# ATA5795 device description
Architecture: AVR8; Family: megaAVR
Registers are 8-bit, access not given, no defined reset value unless marked. A register's access mark holds for its fields unless they carry their own. Offsets are from the block's base; [hi:lo] are bit positions.

## RTC_TIMER
Instances: RTC_TIMER 0x00
0x9E RTCCR — Real-Time Clock Control Register
  [0] RTCR — Real-Time Counter Reset Bit
0x9F RTCDR — Real Time Clock Data Register

## WDT — Watchdog Timer
Instances: WDT 0x00
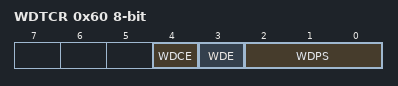
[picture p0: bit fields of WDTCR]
0x60 WDTCR — Watchdog Timer Control Register
  [4] WDCE — Watchdog Change Enable
  [3] WDE — Watch Dog Enable
  [2:0] WDPS — Watch Dog Timer Prescaler Select bits

## PORTC
Instances: PORTC 0x00
0x26 PINC bits used 4:0 — Port C Input Pins
0x27 DDRC bits used 4:0 — Port C Data Direction Register
0x28 PORTC bits used 4:0 — Port C Data Register

## CPU
Instances: CPU 0x00
Parameters: CORE_VERSION=V2E, NEW_INSTRUCTIONS=jmp k:call k
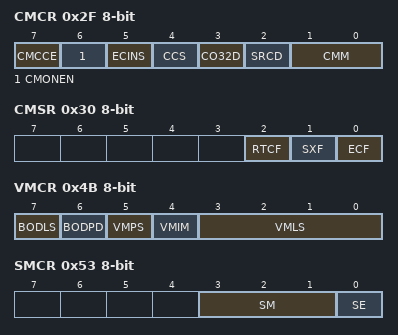
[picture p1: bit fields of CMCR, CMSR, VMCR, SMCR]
0x2F CMCR — Clock Management Control Register
  [7] CMCCE — Clock Management Control Change Enable Bit
  [6] CMONEN — Clock Monitoring Enable Bit
  [5] ECINS — External Clock Input Select Bit
  [4] CCS — Core Clock Select Bit
  [3] CO32D — Crystal Oscillator 32 kHz Disable Bit
  [2] SRCD — Slow RC-oscillator Disable Bit
  [1:0] CMM — Clock Management Mode Bitss
0x30 CMSR — Clock Management Status Register
  [2] RTCF — Real-Time Clock Flag
  [1] SXF — Slow Crystal Oscillator Flag
  [0] ECF — External Clock input Flag Bit
0x36 VMSR — Voltage Monitor Status Register
  [0] VMF — Voltage Monitor Flag
0x3E GPIOR0 — General Purpose I/O Register 0
0x4B VMCR — Voltage Monitor Control Register
  [7] BODLS — Brown-Out Detection Level Select Bit
  [6] BODPD — Brown-Out Detection on Power-Down Bit
  [5] VMPS — Voltage Monitor Power supply Select Bit
  [4] VMIM — Voltage Monitor Interrupt Mask Bit
  [3:0] VMLS — Voltage Monitor Level Select Bits
0x53 SMCR — Sleep Mode Control Register
  [3:1] SM — Sleep Mode Select Bit2
    0=IDLE; 1=EPSAVE (Extended power-save); 2=PDOWN (Power Down); 3=PSAVE (Power Save)
  [0] SE — Sleep Enable Bit
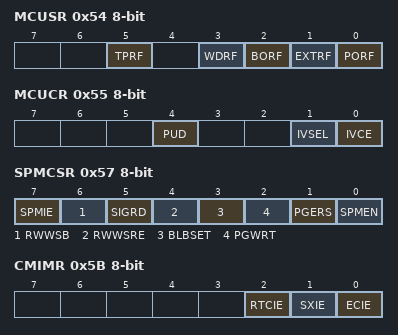
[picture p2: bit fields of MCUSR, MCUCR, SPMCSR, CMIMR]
0x54 MCUSR — MCU Status Register
  [5] TPRF — TransPonder Reset Flag
  [3] WDRF — Watchdog Reset Flag
  [2] BORF — Brown-out Reset Flag
  [1] EXTRF — External Reset Flag
  [0] PORF — Power-on reset flag
0x55 MCUCR — MCU Control Register
  [4] PUD — Pull-up Disable Flag
  [1] IVSEL — Interrupt Vector Select
  [0] IVCE — Interrupt Vector Change Enable
0x57 SPMCSR — Store Program Memory Control Register
  [7] SPMIE — SPM Interrupt Enable
  [6] RWWSB — Read-While-Write Section Busy
  [5] SIGRD — Signature Row Read Bit
  [4] RWWSRE — Read-While-Write section read enable
  [3] BLBSET — Boot Lock Bit Set
  [2] PGWRT — Page Write
  [1] PGERS — Page Erase
  [0] SPMEN — Self Programming Enable
0x5B CMIMR — Clock Management Interrupt Mask Register
  [2] RTCIE — Real-Time Clock Interrupt Enable Bit
  [1] SXIE — Slow Crystal Oscillator Interrupt Enable Bit
  [0] ECIE — External Clock input Interrupt Enable Bit
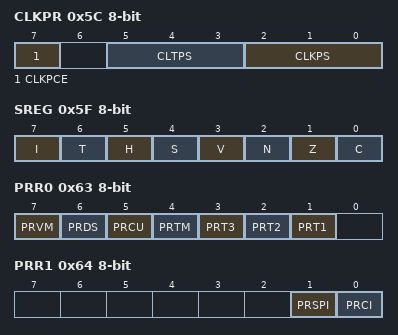
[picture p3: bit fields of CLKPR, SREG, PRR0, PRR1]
0x5C CLKPR — Clock Prescaler Register
  [7] CLKPCE — Clock Prescaler Change Enable Bit
  [5:3] CLTPS — Clock Timer Prescaler Select Bits
  [2:0] CLKPS — Clock system Prescaler Select Bits
0x5D SP 16-bit — Stack Pointer
0x5F SREG — Status Register
  [7] I — Global Interrupt Enable
  [6] T — Bit Copy Storage
  [5] H — Half Carry Flag
  [4] S — Sign Bit
  [3] V — Two's Complement Overflow Flag
  [2] N — Negative Flag
  [1] Z — Zero Flag
  [0] C — Carry Flag
0x63 PRR0 — Power Reduction Register
  [7] PRVM — Power Reduction Voltage Monitor
  [6] PRDS — Power Reduction IR Driver Stage
  [5] PRCU — Power Reduction Crypto Unit
  [4] PRTM — Power Reduction Timer Modulator
  [3] PRT3 — Power Reduction Timer3
  [2] PRT2 — Power Reduction Timer2
  [1] PRT1 — Power Reduction Timer1
0x64 PRR1 — Power Reduction Register
  [1] PRSPI — Power Reduction Serial Peripheral Interface
  [0] PRCI — Power Reduction Contactless Interface
0x65 SRCCAL — SRC-Oscillator Calibration Register
0x66 FRCCAL bits used 5:0 — FRC-Oscillator Calibration Register

## CRC
Instances: CRC 0x00
0xAD CRCDR — CRC Data Register
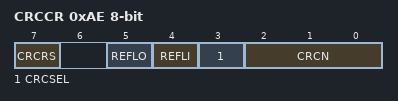
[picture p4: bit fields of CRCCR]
0xAE CRCCR — CRC Control Register
  [7] CRCRS — CRC Reset Bit
  [5] REFLO — Reflect Output Data Bit
  [4] REFLI — Reflect Input Data Bit
  [3] CRCSEL — CRC Mode Select Bit
  [2:0] CRCN — Partial CRC Computation Bits
0xAF CRCSR — CRC Status Register
  [0] CRCBF — CRC Busy Flag
